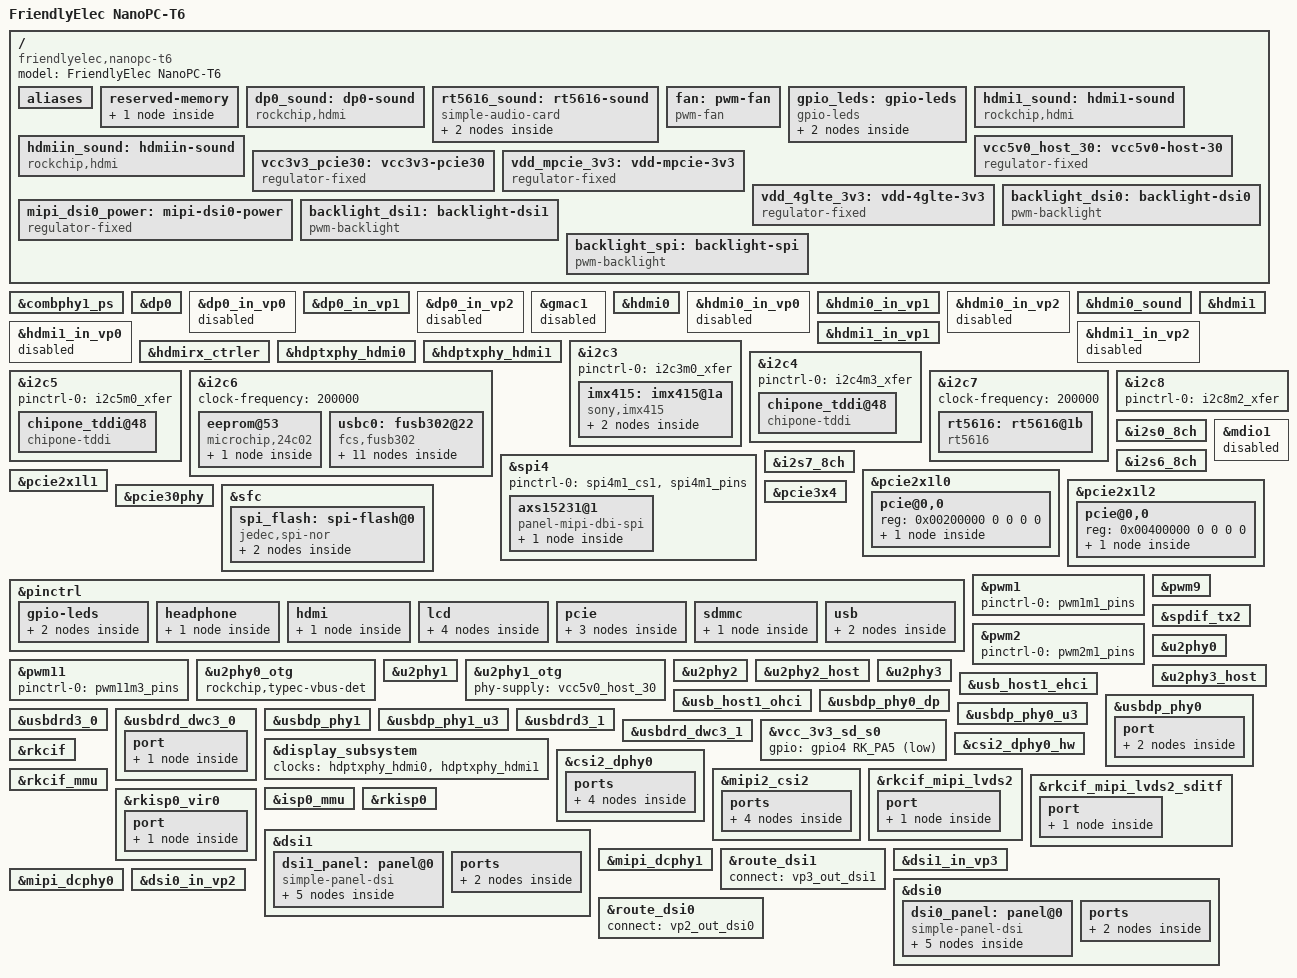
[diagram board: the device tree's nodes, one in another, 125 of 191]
// SPDX-License-Identifier: (GPL-2.0+ OR MIT)
/*
 * Copyright (c) 2022 FriendlyElec Computer Tech. Co., Ltd.
 * (http://www.friendlyelec.com)
 */

/dts-v1/;

#include "rk3588.dtsi"
#include "rk3588s-nanopi-r6-common.dtsi"

/ {
	model = "FriendlyElec NanoPC-T6";
	compatible = "friendlyelec,nanopc-t6", "rockchip,rk3588";

	aliases {
		ethernet0 = &r8125_u10;
		ethernet1 = &r8125_u12;
	};

	/* If hdmirx node is disabled, delete the reserved-memory node here. */
	reserved-memory {
		#address-cells = <2>;
		#size-cells = <2>;
		ranges;

		/* Reserve 256MB memory for hdmirx-controller@fdee0000 */
		cma {
			compatible = "shared-dma-pool";
			reusable;
			reg = <0x0 (256 * 0x100000) 0x0 (256 * 0x100000)>;
			linux,cma-default;
		};
	};

	dp0_sound: dp0-sound {
		status = "okay";
		compatible = "rockchip,hdmi";
		rockchip,card-name = "rockchip-dp0";
		rockchip,mclk-fs = <512>;
		rockchip,cpu = <&spdif_tx2>;
		rockchip,codec = <&dp0 1>;
		rockchip,jack-det;
	};

	rt5616_sound: rt5616-sound {
		status = "okay";
		compatible = "simple-audio-card";
		pinctrl-names = "default";
		pinctrl-0 = <&hp_det>;

		simple-audio-card,name = "realtek,rt5616-codec";
		simple-audio-card,format = "i2s";
		simple-audio-card,mclk-fs = <256>;

		simple-audio-card,hp-det-gpio = <&gpio1 RK_PC4 GPIO_ACTIVE_LOW>;
		simple-audio-card,hp-pin-name = "Headphones";

		simple-audio-card,widgets =
			"Headphone", "Headphones",
			"Microphone", "Microphone Jack";
		simple-audio-card,routing =
			"Headphones", "HPOL",
			"Headphones", "HPOR",
			"MIC1", "Microphone Jack",
			"Microphone Jack", "micbias1";

		simple-audio-card,cpu {
			sound-dai = <&i2s0_8ch>;
		};
		simple-audio-card,codec {
			sound-dai = <&rt5616>;
		};
	};

	fan: pwm-fan {
		status = "okay";
		compatible = "pwm-fan";
		#cooling-cells = <2>;
		fan-supply = <&vcc5v0_sys>;
		pwms = <&pwm1 0 50000 0>;
		cooling-levels = <0 35 64 100 150 255>;
		rockchip,hold-time-ms = <2000>;
		rockchip,temp-trips = <
			50000	1
			55000	2
			60000	3
			65000	4
			70000	5
		>;
	};

	gpio_leds: gpio-leds {
		compatible = "gpio-leds";

		sys_led: led-0 {
			gpios = <&gpio2 RK_PB7 GPIO_ACTIVE_HIGH>;
			label = "sys_led";
			linux,default-trigger = "heartbeat";
			pinctrl-names = "default";
			pinctrl-0 = <&sys_led_pin>;
		};

		usr_led: led-1 {
			gpios = <&gpio2 RK_PC0 GPIO_ACTIVE_HIGH>;
			label = "usr_led";
			pinctrl-names = "default";
			pinctrl-0 = <&usr_led_pin>;
		};
	};

	hdmi1_sound: hdmi1-sound {
		status = "disabled";
		compatible = "rockchip,hdmi";
		rockchip,mclk-fs = <128>;
		rockchip,card-name = "rockchip-hdmi1";
		rockchip,cpu = <&i2s6_8ch>;
		rockchip,codec = <&hdmi1>;
	};

	hdmiin_sound: hdmiin-sound {
		status = "disabled";
		compatible = "rockchip,hdmi";
		rockchip,mclk-fs = <128>;
		rockchip,format = "i2s";
		rockchip,bitclock-master = <&hdmirx_ctrler>;
		rockchip,frame-master = <&hdmirx_ctrler>;
		rockchip,card-name = "rockchip-hdmiin";
		rockchip,cpu = <&i2s7_8ch>;
		rockchip,codec = <&hdmirx_ctrler 0>;
		rockchip,jack-det;
	};

	vcc5v0_host_30: vcc5v0-host-30 {
		compatible = "regulator-fixed";
		enable-active-high;
		gpio = <&gpio4 RK_PB0 GPIO_ACTIVE_HIGH>;
		pinctrl-names = "default";
		pinctrl-0 = <&vcc5v0_host30_en>;
		regulator-name = "vcc5v0_host_30";
		regulator-min-microvolt = <5000000>;
		regulator-max-microvolt = <5000000>;
		vin-supply = <&vcc5v0_usb>;
	};

	vcc3v3_pcie30: vcc3v3-pcie30 {
		compatible = "regulator-fixed";
		enable-active-high;
		gpios = <&gpio2 RK_PC5 GPIO_ACTIVE_HIGH>;
		pinctrl-names = "default";
		pinctrl-0 = <&pcie_m2_0_pwren>;
		regulator-name = "vcc3v3_pcie30";
		regulator-min-microvolt = <3300000>;
		regulator-max-microvolt = <3300000>;
		vin-supply = <&vcc5v0_sys>;
	};

	vdd_mpcie_3v3: vdd-mpcie-3v3 {
		compatible = "regulator-fixed";
		enable-active-high;
		gpio = <&gpio4 RK_PC2 GPIO_ACTIVE_HIGH>;
		pinctrl-names = "default";
		pinctrl-0 = <&pcie_m2_1_pwren>;
		regulator-name = "vdd_mpcie_3v3";
		regulator-min-microvolt = <3300000>;
		regulator-max-microvolt = <3300000>;
		vin-supply = <&vcc5v0_sys>;
	};

	vdd_4glte_3v3: vdd-4glte-3v3 {
		compatible = "regulator-fixed";
		enable-active-high;
		gpio = <&gpio4 RK_PC6 GPIO_ACTIVE_HIGH>;
		regulator-always-on;
		regulator-boot-on;
		regulator-name = "vdd_4glte_3v3";
		regulator-min-microvolt = <3300000>;
		regulator-max-microvolt = <3300000>;
		startup-delay-us = <10000>;
		vin-supply = <&vcc5v0_sys>;
	};

    backlight_dsi0: backlight-dsi0 {
		status = "okay";
		compatible = "pwm-backlight";
		pwms = <&pwm2 0 25000 0>;
		brightness-levels = <
			0  20  20  21  21  22  22  23
			23  24  24  25  25  26  26  27
			27  28  28  29  29  30  30  31
			31  32  32  33  33  34  34  35
			35  36  36  37  37  38  38  39
			40  41  42  43  44  45  46  47
			48  49  50  51  52  53  54  55
			56  57  58  59  60  61  62  63
			64  65  66  67  68  69  70  71
			72  73  74  75  76  77  78  79
			80  81  82  83  84  85  86  87
			88  89  90  91  92  93  94  95
			96  97  98  99 100 101 102 103
			104 105 106 107 108 109 110 111
			112 113 114 115 116 117 118 119
			120 121 122 123 124 125 126 127
			128 129 130 131 132 133 134 135
			136 137 138 139 140 141 142 143
			144 145 146 147 148 149 150 151
			152 153 154 155 156 157 158 159
			160 161 162 163 164 165 166 167
			168 169 170 171 172 173 174 175
			176 177 178 179 180 181 182 183
			184 185 186 187 188 189 190 191
			192 193 194 195 196 197 198 199
			200 201 202 203 204 205 206 207
			208 209 210 211 212 213 214 215
			216 217 218 219 220 221 222 223
			224 225 226 227 228 229 230 231
			232 233 234 235 236 237 238 239
			240 241 242 243 244 245 246 247
			248 249 250 251 252 253 254 255
		>;
		default-brightness-level = <200>;
	};


	mipi_dsi0_power: mipi-dsi0-power {
		compatible = "regulator-fixed";
		regulator-name = "mipi_dsi0_power";
		regulator-min-microvolt = <3300000>;
		regulator-max-microvolt = <3300000>;
	};

	backlight_dsi1: backlight-dsi1 {
		status = "okay";
		compatible = "pwm-backlight";
		pwms = <&pwm11 0 25000 0>;
		brightness-levels = <
			0  20  20  21  21  22  22  23
			23  24  24  25  25  26  26  27
			27  28  28  29  29  30  30  31
			31  32  32  33  33  34  34  35
			35  36  36  37  37  38  38  39
			40  41  42  43  44  45  46  47
			48  49  50  51  52  53  54  55
			56  57  58  59  60  61  62  63
			64  65  66  67  68  69  70  71
			72  73  74  75  76  77  78  79
			80  81  82  83  84  85  86  87
			88  89  90  91  92  93  94  95
			96  97  98  99 100 101 102 103
			104 105 106 107 108 109 110 111
			112 113 114 115 116 117 118 119
			120 121 122 123 124 125 126 127
			128 129 130 131 132 133 134 135
			136 137 138 139 140 141 142 143
			144 145 146 147 148 149 150 151
			152 153 154 155 156 157 158 159
			160 161 162 163 164 165 166 167
			168 169 170 171 172 173 174 175
			176 177 178 179 180 181 182 183
			184 185 186 187 188 189 190 191
			192 193 194 195 196 197 198 199
			200 201 202 203 204 205 206 207
			208 209 210 211 212 213 214 215
			216 217 218 219 220 221 222 223
			224 225 226 227 228 229 230 231
			232 233 234 235 236 237 238 239
			240 241 242 243 244 245 246 247
			248 249 250 251 252 253 254 255
		>;
		default-brightness-level = <200>;
	};

	backlight_spi: backlight-spi {
		status = "okay";
		compatible = "pwm-backlight";
		pwms = <&pwm9 0 25000 0>;
		brightness-levels = <
			0  20  20  21  21  22  22  23
			23  24  24  25  25  26  26  27
			27  28  28  29  29  30  30  31
			31  32  32  33  33  34  34  35
			35  36  36  37  37  38  38  39
			40  41  42  43  44  45  46  47
			48  49  50  51  52  53  54  55
			56  57  58  59  60  61  62  63
			64  65  66  67  68  69  70  71
			72  73  74  75  76  77  78  79
			80  81  82  83  84  85  86  87
			88  89  90  91  92  93  94  95
			96  97  98  99 100 101 102 103
			104 105 106 107 108 109 110 111
			112 113 114 115 116 117 118 119
			120 121 122 123 124 125 126 127
			128 129 130 131 132 133 134 135
			136 137 138 139 140 141 142 143
			144 145 146 147 148 149 150 151
			152 153 154 155 156 157 158 159
			160 161 162 163 164 165 166 167
			168 169 170 171 172 173 174 175
			176 177 178 179 180 181 182 183
			184 185 186 187 188 189 190 191
			192 193 194 195 196 197 198 199
			200 201 202 203 204 205 206 207
			208 209 210 211 212 213 214 215
			216 217 218 219 220 221 222 223
			224 225 226 227 228 229 230 231
			232 233 234 235 236 237 238 239
			240 241 242 243 244 245 246 247
			248 249 250 251 252 253 254 255
		>;
		default-brightness-level = <200>;
	};
};

&combphy1_ps {
	status = "okay";
};

&dp0 {
	status = "okay";
};

&dp0_in_vp0 {
	status = "disabled";
};

&dp0_in_vp1 {
	status = "okay";
};

&dp0_in_vp2 {
	status = "disabled";
};

&dp0_sound {
	status = "okay";
};

&gmac1 {
	status = "disabled";
};

&hdmi0 {
	cec-enable = "true";
	enable-gpios = <&gpio4 RK_PB1 GPIO_ACTIVE_HIGH>;
	status = "okay";
};

&hdmi0_in_vp0 {
	status = "disabled";
};

&hdmi0_in_vp1 {
	status = "okay";
};

&hdmi0_in_vp2 {
	status = "disabled";
};

&hdmi0_sound {
	status = "okay";
};

&hdmi1 {
	cec-enable = "true";
	enable-gpios = <&gpio4 RK_PB2 GPIO_ACTIVE_HIGH>;
	status = "okay";
};

&hdmi1_in_vp0 {
	status = "disabled";
};

&hdmi1_in_vp1 {
	status = "okay";
};

&hdmi1_in_vp2 {
	status = "disabled";
};

&hdmi1_sound {
	status = "okay";
};

&hdmiin_sound {
	status = "okay";
};

/* Should work with at least 128MB cma reserved above. */
&hdmirx_ctrler {
	status = "okay";

	#sound-dai-cells = <1>;
	edid-version = <3>;
	/* Effective level used to trigger HPD: 0-low, 1-high */
	hpd-trigger-level = <1>;
	hdmirx-det-gpios = <&gpio1 RK_PD5 GPIO_ACTIVE_LOW>;
	pinctrl-names = "default";
	pinctrl-0 = <&hdmim1_rx &hdmirx_det>;
};

&hdptxphy_hdmi0 {
	status = "okay";
};

&hdptxphy_hdmi1 {
	status = "okay";
};

&i2c3 {
	pinctrl-0 = <&i2c3m0_xfer>;
	/* connected with MIPI-CSI0 */
};

&i2c4 {
	pinctrl-0 = <&i2c4m3_xfer>;
	/* connected with MIPI-DSI1 */
};

&i2c5 {
	pinctrl-0 = <&i2c5m0_xfer>;
	/* connected with MIPI-DSI0 */
};

&i2c6 {
	clock-frequency = <200000>;
	status = "okay";

	eeprom@53 {
		compatible = "microchip,24c02", "atmel,24c02";
		reg = <0x53>;
		#address-cells = <2>;
		#size-cells = <0>;
		pagesize = <16>;
		size = <256>;

		eui_48: eui-48@fa {
			reg = <0xfa 0x06>;
		};
	};

	usbc0: fusb302@22 {
		compatible = "fcs,fusb302";
		reg = <0x22>;
		interrupt-parent = <&gpio0>;
		interrupts = <RK_PD3 IRQ_TYPE_LEVEL_LOW>;
		int-n-gpios = <&gpio0 RK_PD3 GPIO_ACTIVE_LOW>;
		pinctrl-names = "default";
		pinctrl-0 = <&usbc0_int>;
		vbus-supply = <&vbus5v0_typec>;
		status = "okay";

		ports {
			#address-cells = <1>;
			#size-cells = <0>;

			port@0 {
				reg = <0>;
				usbc0_role_sw: endpoint@0 {
					remote-endpoint = <&dwc3_0_role_switch>;
				};
			};
		};

		usb_con: connector {
			compatible = "usb-c-connector";
			label = "USB-C";
			data-role = "dual";
			power-role = "dual";
			try-power-role = "sink";
			op-sink-microwatt = <1000000>;
			sink-pdos =
				<PDO_FIXED(5000, 3000, PDO_FIXED_USB_COMM)>;
			source-pdos =
				<PDO_FIXED(5000, 2000, PDO_FIXED_USB_COMM)>;

			altmodes {
				#address-cells = <1>;
				#size-cells = <0>;

				altmode@0 {
					reg = <0>;
					svid = <0xff01>;
					vdo = <0xffffffff>;
				};
			};

			ports {
				#address-cells = <1>;
				#size-cells = <0>;

				port@0 {
					reg = <0>;
					usbc0_orien_sw: endpoint {
						remote-endpoint = <&usbdp_phy0_orientation_switch>;
					};
				};

				port@1 {
					reg = <1>;
					dp_altmode_mux: endpoint {
						remote-endpoint = <&usbdp_phy0_dp_altmode_mux>;
					};
				};
			};
		};
	};
};

&i2c7 {
	clock-frequency = <200000>;
	status = "okay";

	rt5616: rt5616@1b {
		status = "okay";
		#sound-dai-cells = <0>;
		compatible = "rt5616";
		reg = <0x1b>;
		clocks = <&mclkout_i2s0>;
		clock-names = "mclk";
		assigned-clocks = <&mclkout_i2s0>;
		assigned-clock-rates = <12288000>;
		pinctrl-names = "default";
		pinctrl-0 = <&i2s0_mclk>;
	};

	/* connected with MIPI-CSI1 */
};

&i2c8 {
	pinctrl-0 = <&i2c8m2_xfer>;
	status = "okay";
};

&spi4 {
	pinctrl-0 = <&spi4m1_cs1 &spi4m1_pins>;
	status = "okay";

	axs15231@1 {
		compatible = "panel-mipi-dbi-spi";
		reg = <1>;
		spi-max-frequency = <80000000>;
		reset-gpios = <&gpio1 RK_PA7 GPIO_ACTIVE_HIGH>;
		dc-gpios = <&gpio3 RK_PC2 GPIO_ACTIVE_LOW>;
		power-supply = <&mipi_dsi0_power>;
		backlight = <&backlight_spi>;
		width-mm = <26>;
        height-mm = <92>;
		write-only;
		timing: panel-timing {
            hactive = <172>; // 横向分辨率
            vactive = <640>; // 纵向分辨率
            hback-porch = <0>;
            vback-porch = <0>;

            clock-frequency = <0>;
            hfront-porch = <0>;
            hsync-len = <0>;
            vfront-porch = <0>;
            vsync-len = <0>;
        };
	};
};

&i2s0_8ch {
	status = "okay";
	pinctrl-0 = <&i2s0_lrck
		     &i2s0_sclk
		     &i2s0_sdi0
		     &i2s0_sdo0>;
	rockchip,trcm-sync-tx-only;
};

&i2s6_8ch {
	status = "okay";
};

&i2s7_8ch {
	status = "okay";
};

&mdio1 {
	status = "disabled";
};

&pcie2x1l0 {
	reset-gpios = <&gpio4 RK_PB3 GPIO_ACTIVE_HIGH>;
	rockchip,init-delay-ms = <100>;
	vpcie3v3-supply = <&vcc_3v3_pcie20>;
	status = "okay";

	pcie@0,0 {
		reg = <0x00200000 0 0 0 0>;
		#address-cells = <3>;
		#size-cells = <2>;

		r8125_u12: pcie@20,0 {
			reg = <0x000000 0 0 0 0>;
			local-mac-address = [ 00 00 00 00 00 00 ];
		};
	};
};

&pcie2x1l1 {
	reset-gpios = <&gpio4 RK_PA2 GPIO_ACTIVE_HIGH>;
	rockchip,init-delay-ms = <500>;
	vpcie3v3-supply = <&vdd_mpcie_3v3>;
	status = "okay";
};

&pcie2x1l2 {
	reset-gpios = <&gpio4 RK_PA4 GPIO_ACTIVE_HIGH>;
	vpcie3v3-supply = <&vcc_3v3_pcie20>;
	status = "okay";

	pcie@0,0 {
		reg = <0x00400000 0 0 0 0>;
		#address-cells = <3>;
		#size-cells = <2>;

		r8125_u10: pcie@40,0 {
			reg = <0x000000 0 0 0 0>;
			local-mac-address = [ 00 00 00 00 00 00 ];
		};
	};
};

&pcie30phy {
	status = "okay";
};

&pcie3x4 {
	pinctrl-names = "default";
	pinctrl-0 = <&pcie30x4_clkreqn_m1>;
	reset-gpios = <&gpio4 RK_PB6 GPIO_ACTIVE_HIGH>;
	vpcie3v3-supply = <&vcc3v3_pcie30>;
	status = "okay";
};

&sfc {
	status = "okay";
	max-freq = <50000000>;
	#address-cells = <1>;
	#size-cells = <0>;
	pinctrl-names = "default";
	pinctrl-0 = <&fspim1_pins>;

	spi_flash: spi-flash@0 {
		#address-cells = <1>;
		#size-cells = <0>;
		compatible = "jedec,spi-nor";
		reg = <0x0>;
		spi-max-frequency = <50000000>;
		spi-tx-bus-width = <1>;
		spi-rx-bus-width = <4>;
		status = "okay";

		partitions {
			compatible = "fixed-partitions";
			#address-cells = <1>;
			#size-cells = <1>;

			loader@0 {
				label = "loader";
				reg = <0x0 0x1000000>;
			};
		};
	};
};

&pinctrl {
	gpio-leds {
		sys_led_pin: sys-led-pin {
			rockchip,pins = <2 RK_PB7 RK_FUNC_GPIO &pcfg_pull_none>;
		};

		usr_led_pin: usr-led-pin {
			rockchip,pins = <2 RK_PC0 RK_FUNC_GPIO &pcfg_pull_none>;
		};
	};

	headphone {
		hp_det: hp-det {
			rockchip,pins = <1 RK_PC4 RK_FUNC_GPIO &pcfg_pull_none>;
		};
	};

	hdmi {
		hdmirx_det: hdmirx-det {
			rockchip,pins = <1 RK_PD5 RK_FUNC_GPIO &pcfg_pull_up>;
		};
	};

	lcd {
		/omit-if-no-ref/
		lcd_rst0_gpio: lcd-rst0-gpio {
			rockchip,pins = <3 RK_PA6 RK_FUNC_GPIO &pcfg_pull_none>;
		};

		/omit-if-no-ref/
		lcd_rst1_gpio: lcd-rst1-gpio {
			rockchip,pins = <4 RK_PA3 RK_FUNC_GPIO &pcfg_pull_none>;
		};

		/omit-if-no-ref/
		touch_dsi0_gpio: touch-dsi0-gpio {
			rockchip,pins =
				<3 RK_PC0 RK_FUNC_GPIO &pcfg_pull_up>,
				<3 RK_PC1 RK_FUNC_GPIO &pcfg_pull_none>;
		};

		/omit-if-no-ref/
		touch_dsi1_gpio: touch-dsi1-gpio {
			rockchip,pins =
				<4 RK_PA0 RK_FUNC_GPIO &pcfg_pull_up>,
				<4 RK_PA1 RK_FUNC_GPIO &pcfg_pull_none>;
		};
	};

	pcie {
		pcie_m2_0_pwren: pcie-m20-pwren {
			rockchip,pins = <2 RK_PC5 RK_FUNC_GPIO &pcfg_pull_none>;
		};

		pcie_m2_1_pwren: pcie-m21-pwren {
			rockchip,pins = <4 RK_PC2 RK_FUNC_GPIO &pcfg_pull_none>;
		};

		pcie30x4_clkreqn_m1: pcie30x4-clkreqn-m1 {
			rockchip,pins = <4 RK_PB4 RK_FUNC_GPIO &pcfg_pull_down>;
		};
	};

	sdmmc {
		sd_s0_pwr: sd-s0-pwr {
			rockchip,pins = <4 RK_PA5 RK_FUNC_GPIO &pcfg_pull_down>;
		};
	};

	usb {
		vcc5v0_host30_en: vcc5v0-host30-en {
			rockchip,pins = <4 RK_PB0 RK_FUNC_GPIO &pcfg_pull_none>;
		};

		/omit-if-no-ref/
		vcc5v0_host20_en: vcc5v0-host20-en {
			rockchip,pins = <1 RK_PA4 RK_FUNC_GPIO &pcfg_pull_none>;
		};
	};
};

&pwm1 {
	pinctrl-0 = <&pwm1m1_pins>;
	status = "okay";
};

&pwm2 {
	pinctrl-0 = <&pwm2m1_pins>;
	/* connected with MIPI-DSI0 */
	status = "okay";
};

&pwm9 {
	status = "okay";
};

&pwm11 {
	pinctrl-0 = <&pwm11m3_pins>;
	/* connected with MIPI-DSI1 */
	status = "okay";
};

&spdif_tx2 {
	status = "okay";
};

&u2phy0 {
	status = "okay";
};

&u2phy0_otg {
	rockchip,typec-vbus-det;
	status = "okay";
};

&u2phy1 {
	status = "okay";
};

&u2phy1_otg {
	phy-supply = <&vcc5v0_host_30>;
	status = "okay";
};

&u2phy2 {
	status = "okay";
};

&u2phy2_host {
	status = "okay";
};

&u2phy3 {
	status = "okay";
};

&u2phy3_host {
	status = "okay";
};

&usb_host1_ehci {
	status = "okay";
};

&usb_host1_ohci {
	status = "okay";
};

&usbdp_phy0 {
	orientation-switch;
	rockchip,dp-lane-mux = <0 1 2 3 >;
	svid = <0xff01>;
	sbu1-dc-gpios = <&gpio4 RK_PA6 GPIO_ACTIVE_HIGH>;
	sbu2-dc-gpios = <&gpio4 RK_PA7 GPIO_ACTIVE_HIGH>;
	status = "okay";

	port {
		#address-cells = <1>;
		#size-cells = <0>;
		usbdp_phy0_orientation_switch: endpoint@0 {
			reg = <0>;
			remote-endpoint = <&usbc0_orien_sw>;
		};

		usbdp_phy0_dp_altmode_mux: endpoint@1 {
			reg = <1>;
			remote-endpoint = <&dp_altmode_mux>;
		};
	};
};

&usbdp_phy0_dp {
	status = "okay";
};

&usbdp_phy0_u3 {
	status = "okay";
};

&usbdrd3_0 {
	status = "okay";
};

&usbdrd_dwc3_0 {
	dr_mode = "otg";
	usb-role-switch;
	status = "okay";

	port {
		#address-cells = <1>;
		#size-cells = <0>;
		dwc3_0_role_switch: endpoint@0 {
			reg = <0>;
			remote-endpoint = <&usbc0_role_sw>;
		};
	};
};

&usbdp_phy1 {
	status = "okay";
};

&usbdp_phy1_u3 {
	status = "okay";
};

&usbdrd3_1 {
	status = "okay";
};

&usbdrd_dwc3_1 {
	dr_mode = "host";
	snps,xhci-trb-ent-quirk;
	status = "okay";
};

&vcc_3v3_sd_s0 {
	/delete-property/ enable-active-high;
	gpio = <&gpio4 RK_PA5 GPIO_ACTIVE_LOW>;
};


&display_subsystem {
	clocks = <&hdptxphy_hdmi0>, <&hdptxphy_hdmi1>;
	clock-names = "hdmi0_phy_pll", "hdmi1_phy_pll";
};

&i2c3 {
	status = "okay";
	#address-cells = <1>;
	#size-cells = <0>;

	imx415: imx415@1a {
		status = "okay";
		compatible = "sony,imx415";
		reg = <0x1a>;
		clocks = <&cru CLK_MIPI_CAMARAOUT_M1>;
		clock-names = "xvclk";
		pinctrl-names = "default";
		pinctrl-0 = <&mipim0_camera1_clk>;
		power-domains = <&power RK3588_PD_VI>;
		pwdn-gpios = <&gpio4 RK_PD5 GPIO_ACTIVE_HIGH>;
		reset-gpios = <&gpio4 RK_PC4 GPIO_ACTIVE_LOW>;
		rockchip,camera-module-index = <0>;
		rockchip,camera-module-facing = "back";
		rockchip,camera-module-name = "RADXA-CAMERA-4K";
		rockchip,camera-module-lens-name = "DEFAULT";
		port {
			imx415_out0: endpoint {
				remote-endpoint = <&mipidphy0_in_ucam0>;
				data-lanes = <1 2 3 4>;
			};
		};
	};
};

&csi2_dphy0_hw {
	status = "okay";
};

&csi2_dphy0 {
	status = "okay";

	ports {
		#address-cells = <1>;
		#size-cells = <0>;

		port@0 {
			reg = <0>;
			#address-cells = <1>;
			#size-cells = <0>;

			mipidphy0_in_ucam0: endpoint@1 {
				reg = <1>;
				remote-endpoint = <&imx415_out0>;
				data-lanes = <1 2 3 4>;
			};
		};

		port@1 {
			reg = <1>;
			#address-cells = <1>;
			#size-cells = <0>;

			csidphy0_out: endpoint@0 {
				reg = <0>;
				remote-endpoint = <&mipi2_csi2_input>;
			};
		};
	};
};

&mipi2_csi2 {
	status = "okay";

	ports {
		#address-cells = <1>;
		#size-cells = <0>;

		port@0 {
			reg = <0>;
			#address-cells = <1>;
			#size-cells = <0>;

			mipi2_csi2_input: endpoint@1 {
				reg = <1>;
				remote-endpoint = <&csidphy0_out>;
			};
		};

		port@1 {
			reg = <1>;
			#address-cells = <1>;
			#size-cells = <0>;

			mipi2_csi2_output: endpoint@0 {
				reg = <0>;
				remote-endpoint = <&cif_mipi0_in0>;
			};
		};
	};
};

&rkcif {
	status = "okay";
};

&rkcif_mipi_lvds2 {
	status = "okay";

	port {
		cif_mipi0_in0: endpoint {
			remote-endpoint = <&mipi2_csi2_output>;
		};
	};
};

&rkcif_mipi_lvds2_sditf {
	status = "okay";

	port {
		mipi_lvds2_sditf: endpoint {
			remote-endpoint = <&isp0_vir0>;
		};
	};
};

&rkcif_mmu {
	status = "okay";
};

&isp0_mmu {
	status = "okay";
};

&rkisp0 {
	status = "okay";
};

&rkisp0_vir0 {
	status = "okay";

	port {
		#address-cells = <1>;
		#size-cells = <0>;

		isp0_vir0: endpoint@0 {
			reg = <0>;
			remote-endpoint = <&mipi_lvds2_sditf>;
		};
	};
};

&dsi1 {
	status = "okay";
	#address-cells = <1>;
	#size-cells = <0>;
	dsi1_panel: panel@0 {
		status = "okay";
		compatible = "simple-panel-dsi";
		reg = <0>;
		backlight = <&backlight_dsi1>;
		power-supply = <&mipi_dsi0_power>;
		reset-gpios = <&gpio4 RK_PA3 GPIO_ACTIVE_LOW>;
		enable-delay-ms = <35>;
		prepare-delay-ms = <6>;
		reset-delay-ms = <10>;
		init-delay-ms = <150>;
		unprepare-delay-ms = <0>;
		disable-delay-ms = <20>;

		size,width = <74>;
		size,height = <133>;

		dsi,flags = <(MIPI_DSI_MODE_VIDEO | MIPI_DSI_MODE_VIDEO_BURST | MIPI_DSI_MODE_LPM | MIPI_DSI_MODE_NO_EOT_PACKET)>;
		dsi,format = <MIPI_DSI_FMT_RGB888>;
		dsi,lanes  = <4>;

		panel-init-sequence = [
			39 00 04 F0 99 22 0C
			39 00 09 9D 00 00 04 1C 22 3A 40 58
			39 00 21 B2 07 06 05 04 22 22 05 05 00 00 00 00 00 00 00 00 00 01 6E 00 00 00 00 00 00 55 55 05 10 20 11 00
			39 00 21 B3 70 03 01 01 81 02 00 00 5A 00 00 00 00 00 03 FF C0 00 00 00 03 FF C0 00 00 00 00 00 00 00 00 00
			39 00 21 B4 31 01 01 01 01 81 00 00 00 00 00 00 00 00 03 FF C0 00 00 00 03 FF C0 00 00 00 00 00 00 00 00 00
			39 00 21 B6 1C 1C 1D 1D 1E 1E 82 3A 3A 82 C0 82 00 82 05 00 0D 0F 11 13 82 EC 82 ED FC 08 00 00 00 00 3C 00
			39 00 21 B7 1C 1C 1D 1D 1E 1E 82 3A 3A 82 C0 82 00 82 04 00 0C 0E 10 12 82 EC 82 ED FC 08 00 00 00 00 3C 00
			39 00 21 B9 12 33 21 12 33 21 12 33 21 12 33 21 12 33 21 12 33 21 12 33 21 12 33 21 00 00 0F 00 00 00 00 02
			39 00 21 BA 00 55 55 55 55 55 55 55 55 55 55 55 55 00 00 00 00 00 03 00 00 00 00 00 03 00 00 00 00 00 00 00
			39 00 21 BB 01 02 03 0A 04 13 14 12 16 5C 00 15 16 00 00 00 00 00 00 00 00 00 00 00 00 00 00 00 00 00 00 00
			39 00 21 BC 00 00 00 00 04 00 FF F8 0B 11 50 5C 55 99 00 00 00 00 00 00 00 00 00 00 00 00 00 00 00 00 00 00
			39 00 07 BD A1 A2 52 2E 00 8F
			39 00 21 BE 23 0B 0B 0A 43 35 33 32 14 00 00 3A 00 00 00 00 00 00 00 00 00 00 00 00 00 00 00 00 00 00 00 00
			39 00 17 C0 40 93 FF FF FF 3F FF 00 FF 00 CC 04 12 35 67 89 A0 FF FF F0 0B EB
			39 00 21 C1 00 00 20 26 C0 04 20 20 04 80 17 24 50 00 10 07 11 84 A0 00 93 10 10 00 00 00 00 00 00 00 00 00
			39 00 21 C3 00 00 03 01 00 01 1D 1C 1C 22 22 22 00 FF 40 4D 2A 2A 2A 2A 2A 2A 2A 2A 00 00 00 00 00 00 00 00
			39 00 21 C4 0C 97 A8 29 C0 3C 01 A0 00 0A 26 48 91 B3 75 00 F0 00 00 00 00 00 00 00 00 00 00 00 00 00 00 00
			39 00 21 C5 02 45 C8 40 78 04 02 02 08 04 14 42 05 03 01 20 0D 0A 05 12 80 00 00 00 00 00 00 00 00 00 00 00
			39 00 21 C6 0A 13 28 46 46 28 3F 12 0D 0D 06 00 37 00 00 00 00 00 00 00 00 00 00 00 00 00 00 00 00 00 00 00
			39 00 21 99 91 CB 01 3F 00 7A 00 30 22 01 A2 00 BA 00 24 05 24 05 00 00 00 00 00 00 00 00 00 00 00 00 00 00
			39 00 21 9A 11 35 01 00 FF 00 0A 00 17 00 22 6A 00 B9 B9 00 00 00 00 00 00 00 00 00 00 00 00 00 00 00 00 00
			15 00 02 C2 00
			39 00 1C C7 77 77 77 77 77 77 77 77 20 77 77 77 77 77 77 77 77 20 43 00 01 FF FF 40 DC DC 00
			39 00 21 80 FF F6 E8 DE D6 CF C8 C3 BE AE A2 98 90 89 83 78 6F 67 5F 5F 57 50 48 3E 39 34 2D 25 1C 11 0F 0D
			39 00 21 81 FF F6 E8 DE D6 CF C8 C3 BE AE A2 98 90 89 83 78 6F 67 5F 5F 57 50 48 3E 39 34 2D 25 1C 11 0F 0D
			39 00 21 82 FF F6 E8 DE D6 CF C8 C3 BE AE A2 98 90 89 83 78 6F 67 5F 5F 57 50 48 3E 39 34 2D 25 1C 11 0F 0D
			39 00 21 83 09 0B 08 06 02 00 00 0B 08 06 02 00 00 0B 08 06 02 00 00 12 0E 0A 06 02 00 12 0E 0A 06 02 00 12
			39 00 21 84 0E 0A 06 02 00 2E 0D AB A6 48 83 CB E1 7B 42 E0 DA BA 64 88 3C BE 17 B4 2E 0D AB A6 48 83 CB E1
			39 00 1F 85 7B 40 00 00 00 00 00 00 00 00 00 00 00 00 00 00 00 00 00 00 00 00 00 00 00 00 00 00 00 00
			39 00 0F D0 0C 23 18 00 00 00 80 0C DF 0F 40 00 08 18
			39 00 03 91 F1 00
			15 00 02 35 00
			05 78 01 11
			05 32 01 29
			15 00 02 AC 05
		];

		panel-exit-sequence = [
			05 78 01 28
			05 00 01 10
		];

		disp1_timings: display-timings {
			native-mode = <&dsi1_timing0>;
			dsi1_timing0: timing0 {
				clock-frequency = <137000000>;
				hactive = <1080>;
				vactive = <1920>;
				hback-porch = <32>;
				hfront-porch = <32>;
				vback-porch = <32>;
				vfront-porch = <38>;
				hsync-len = <4>;
				vsync-len = <4>;
				hsync-active = <0>;
				vsync-active = <0>;
				de-active = <0>;
				pixelclk-active = <0>;
			};
		};

		ports {
			#address-cells = <1>;
			#size-cells = <0>;
			port@0 {
				reg = <0>;
				panel_in_dsi1: endpoint {
					remote-endpoint = <&dsi1_out_panel>;
				};
			};
		};
	};

	ports {
		#address-cells = <1>;
		#size-cells = <0>;
			port@1 {
			reg = <1>;
			dsi1_out_panel: endpoint {
				remote-endpoint = <&panel_in_dsi1>;
			};
		};
	};
};

&mipi_dcphy1 {
	status = "okay";
};

&route_dsi1 {
	status = "okay";
	connect = <&vp3_out_dsi1>;
};

&dsi1_in_vp3 {
	status = "okay";
};

&dsi0 {
	status = "okay";
	#address-cells = <1>;
	#size-cells = <0>;
	dsi0_panel: panel@0 {
		status = "okay";
		compatible = "simple-panel-dsi";
		reg = <0>;
		backlight = <&backlight_dsi0>;
		power-supply = <&mipi_dsi0_power>;
		reset-gpios = <&gpio3 RK_PA6 GPIO_ACTIVE_LOW>;
		enable-delay-ms = <35>;
		prepare-delay-ms = <6>;
		reset-delay-ms = <10>;
		init-delay-ms = <150>;
		unprepare-delay-ms = <0>;
		disable-delay-ms = <20>;

		size,width = <74>;
		size,height = <133>;

		dsi,flags = <(MIPI_DSI_MODE_VIDEO | MIPI_DSI_MODE_VIDEO_BURST | MIPI_DSI_MODE_LPM | MIPI_DSI_MODE_NO_EOT_PACKET)>;
		dsi,format = <MIPI_DSI_FMT_RGB888>;
		dsi,lanes  = <4>;

		panel-init-sequence = [
			39 00 04 F0 99 22 0C
			39 00 09 9D 00 00 04 1C 22 3A 40 58
			39 00 21 B2 07 06 05 04 22 22 05 05 00 00 00 00 00 00 00 00 00 01 6E 00 00 00 00 00 00 55 55 05 10 20 11 00
			39 00 21 B3 70 03 01 01 81 02 00 00 5A 00 00 00 00 00 03 FF C0 00 00 00 03 FF C0 00 00 00 00 00 00 00 00 00
			39 00 21 B4 31 01 01 01 01 81 00 00 00 00 00 00 00 00 03 FF C0 00 00 00 03 FF C0 00 00 00 00 00 00 00 00 00
			39 00 21 B6 1C 1C 1D 1D 1E 1E 82 3A 3A 82 C0 82 00 82 05 00 0D 0F 11 13 82 EC 82 ED FC 08 00 00 00 00 3C 00
			39 00 21 B7 1C 1C 1D 1D 1E 1E 82 3A 3A 82 C0 82 00 82 04 00 0C 0E 10 12 82 EC 82 ED FC 08 00 00 00 00 3C 00
			39 00 21 B9 12 33 21 12 33 21 12 33 21 12 33 21 12 33 21 12 33 21 12 33 21 12 33 21 00 00 0F 00 00 00 00 02
			39 00 21 BA 00 55 55 55 55 55 55 55 55 55 55 55 55 00 00 00 00 00 03 00 00 00 00 00 03 00 00 00 00 00 00 00
			39 00 21 BB 01 02 03 0A 04 13 14 12 16 5C 00 15 16 00 00 00 00 00 00 00 00 00 00 00 00 00 00 00 00 00 00 00
			39 00 21 BC 00 00 00 00 04 00 FF F8 0B 11 50 5C 55 99 00 00 00 00 00 00 00 00 00 00 00 00 00 00 00 00 00 00
			39 00 07 BD A1 A2 52 2E 00 8F
			39 00 21 BE 23 0B 0B 0A 43 35 33 32 14 00 00 3A 00 00 00 00 00 00 00 00 00 00 00 00 00 00 00 00 00 00 00 00
			39 00 17 C0 40 93 FF FF FF 3F FF 00 FF 00 CC 04 12 35 67 89 A0 FF FF F0 0B EB
			39 00 21 C1 00 00 20 26 C0 04 20 20 04 80 17 24 50 00 10 07 11 84 A0 00 93 10 10 00 00 00 00 00 00 00 00 00
			39 00 21 C3 00 00 03 01 00 01 1D 1C 1C 22 22 22 00 FF 40 4D 2A 2A 2A 2A 2A 2A 2A 2A 00 00 00 00 00 00 00 00
			39 00 21 C4 0C 97 A8 29 C0 3C 01 A0 00 0A 26 48 91 B3 75 00 F0 00 00 00 00 00 00 00 00 00 00 00 00 00 00 00
			39 00 21 C5 02 45 C8 40 78 04 02 02 08 04 14 42 05 03 01 20 0D 0A 05 12 80 00 00 00 00 00 00 00 00 00 00 00
			39 00 21 C6 0A 13 28 46 46 28 3F 12 0D 0D 06 00 37 00 00 00 00 00 00 00 00 00 00 00 00 00 00 00 00 00 00 00
			39 00 21 99 91 CB 01 3F 00 7A 00 30 22 01 A2 00 BA 00 24 05 24 05 00 00 00 00 00 00 00 00 00 00 00 00 00 00
			39 00 21 9A 11 35 01 00 FF 00 0A 00 17 00 22 6A 00 B9 B9 00 00 00 00 00 00 00 00 00 00 00 00 00 00 00 00 00
			15 00 02 C2 00
			39 00 1C C7 77 77 77 77 77 77 77 77 20 77 77 77 77 77 77 77 77 20 43 00 01 FF FF 40 DC DC 00
			39 00 21 80 FF F6 E8 DE D6 CF C8 C3 BE AE A2 98 90 89 83 78 6F 67 5F 5F 57 50 48 3E 39 34 2D 25 1C 11 0F 0D
			39 00 21 81 FF F6 E8 DE D6 CF C8 C3 BE AE A2 98 90 89 83 78 6F 67 5F 5F 57 50 48 3E 39 34 2D 25 1C 11 0F 0D
			39 00 21 82 FF F6 E8 DE D6 CF C8 C3 BE AE A2 98 90 89 83 78 6F 67 5F 5F 57 50 48 3E 39 34 2D 25 1C 11 0F 0D
			39 00 21 83 09 0B 08 06 02 00 00 0B 08 06 02 00 00 0B 08 06 02 00 00 12 0E 0A 06 02 00 12 0E 0A 06 02 00 12
			39 00 21 84 0E 0A 06 02 00 2E 0D AB A6 48 83 CB E1 7B 42 E0 DA BA 64 88 3C BE 17 B4 2E 0D AB A6 48 83 CB E1
			39 00 1F 85 7B 40 00 00 00 00 00 00 00 00 00 00 00 00 00 00 00 00 00 00 00 00 00 00 00 00 00 00 00 00
			39 00 0F D0 0C 23 18 00 00 00 80 0C DF 0F 40 00 08 18
			39 00 03 91 F1 00
			15 00 02 35 00
			05 78 01 11
			05 32 01 29
			15 00 02 AC 05
		];

		panel-exit-sequence = [
			05 78 01 28
			05 00 01 10
		];

		disp0_timings0: display-timings {
			native-mode = <&dsi0_timing0>;
			dsi0_timing0: timing0 {
				clock-frequency = <137000000>;
				hactive = <1080>;
				vactive = <1920>;
				hback-porch = <32>;
				hfront-porch = <32>;
				vback-porch = <32>;
				vfront-porch = <38>;
				hsync-len = <4>;
				vsync-len = <4>;
				hsync-active = <0>;
				vsync-active = <0>;
				de-active = <0>;
				pixelclk-active = <0>;
			};
		};

		ports {
			#address-cells = <1>;
			#size-cells = <0>;
			port@0 {
				reg = <0>;
				panel_in_dsi0: endpoint {
					remote-endpoint = <&dsi0_out_panel>;
				};
			};
		};
	};

	ports {
		#address-cells = <1>;
		#size-cells = <0>;
			port@1 {
			reg = <1>;
			dsi0_out_panel: endpoint {
				remote-endpoint = <&panel_in_dsi0>;
			};
		};
	};
};

&mipi_dcphy0 {
	status = "okay";
};

&route_dsi0 {
	status = "okay";
	connect = <&vp2_out_dsi0>;
};

&dsi0_in_vp2 {
	status = "okay";
};

&i2c4 {
	pinctrl-0 = <&i2c4m3_xfer>;
	status = "okay";

	chipone_tddi@48 {
		compatible = "chipone-tddi";
		reg = <0x48>;
		interrupt-parent = <&gpio4>;
		interrupts = <RK_PA0 0x2008>;
		chipone,rst-gpio = <&gpio4 RK_PA1 GPIO_ACTIVE_HIGH>;
		chipone,irq-gpio = <&gpio4 RK_PA0 GPIO_ACTIVE_HIGH>;
		chipone,x-res = <1080>;
		chipone,y-res = <1920>;
		/* Charger detect */
		chipone,touch-charger-detect-enable;
		chipone,touch-charger-detect-type = "notify";/* notify,poll*/
		chipone,touch-charger-detect-psy-name = "charger";/* usb */
		chipone,touch-charger-detect-psp = " POWER_SUPPLY_PROP_ONLINE ";
		chipone,touch-charger-detect-psp-poll-interval = <1000>;
		/* Earjack detect (unused on this platform) */
		// chipone,touch-earjack-detect-enable;
		// chipone,touch-earjack-state-filepath =
		// "/sys/bus/platform/drivers/Accdet_Driver/state";
		// chipone,touch-earjack-poll-interval = <1000>;
		rockchip,panel-notifier = <&dsi1_panel>;
	};
};

&i2c5 {
	status = "okay";

	chipone_tddi@48 {
		compatible = "chipone-tddi";
		reg = <0x48>;
		interrupt-parent = <&gpio3>;
		interrupts = <RK_PC0 0x2008>;
		chipone,rst-gpio = <&gpio3 RK_PC1 GPIO_ACTIVE_HIGH>;
		chipone,irq-gpio = <&gpio3 RK_PC0 GPIO_ACTIVE_HIGH>;
		chipone,x-res = <1080>;
		chipone,y-res = <1920>;
		/* Note: For independent displays, coordinate offset is not needed.
		 * User-space should map input devices to displays via device name
		 * (chipone-tddi-i2c4 / chipone-tddi-i2c5) or panel_name sysfs attribute.
		 */
		/* Charger detect */
		chipone,touch-charger-detect-enable;
		chipone,touch-charger-detect-type = "notify";/* notify,poll*/
		chipone,touch-charger-detect-psy-name = "charger";/* usb */
		chipone,touch-charger-detect-psp = " POWER_SUPPLY_PROP_ONLINE ";
		chipone,touch-charger-detect-psp-poll-interval = <1000>;
		/* Earjack detect (unused on this platform) */
		// chipone,touch-earjack-detect-enable;
		// chipone,touch-earjack-state-filepath =
		// "/sys/bus/platform/drivers/Accdet_Driver/state";
		// chipone,touch-earjack-poll-interval = <1000>;
		rockchip,panel-notifier = <&dsi0_panel>;
	};
};
